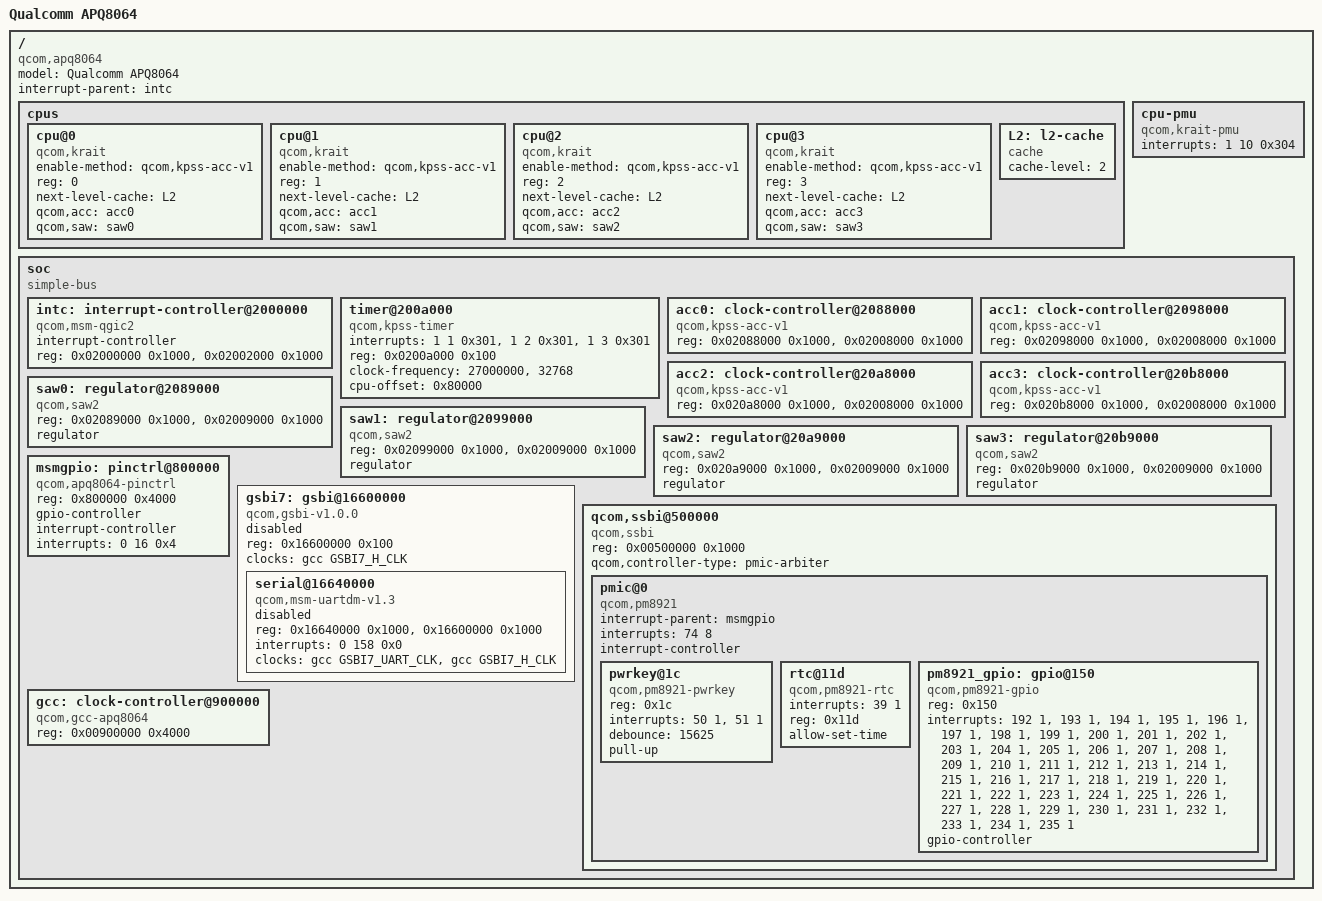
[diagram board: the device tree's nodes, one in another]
/dts-v1/;

#include "skeleton.dtsi"
#include <dt-bindings/clock/qcom,gcc-msm8960.h>
#include <dt-bindings/soc/qcom,gsbi.h>

/ {
	model = "Qualcomm APQ8064";
	compatible = "qcom,apq8064";
	interrupt-parent = <&intc>;

	cpus {
		#address-cells = <1>;
		#size-cells = <0>;

		cpu@0 {
			compatible = "qcom,krait";
			enable-method = "qcom,kpss-acc-v1";
			device_type = "cpu";
			reg = <0>;
			next-level-cache = <&L2>;
			qcom,acc = <&acc0>;
			qcom,saw = <&saw0>;
		};

		cpu@1 {
			compatible = "qcom,krait";
			enable-method = "qcom,kpss-acc-v1";
			device_type = "cpu";
			reg = <1>;
			next-level-cache = <&L2>;
			qcom,acc = <&acc1>;
			qcom,saw = <&saw1>;
		};

		cpu@2 {
			compatible = "qcom,krait";
			enable-method = "qcom,kpss-acc-v1";
			device_type = "cpu";
			reg = <2>;
			next-level-cache = <&L2>;
			qcom,acc = <&acc2>;
			qcom,saw = <&saw2>;
		};

		cpu@3 {
			compatible = "qcom,krait";
			enable-method = "qcom,kpss-acc-v1";
			device_type = "cpu";
			reg = <3>;
			next-level-cache = <&L2>;
			qcom,acc = <&acc3>;
			qcom,saw = <&saw3>;
		};

		L2: l2-cache {
			compatible = "cache";
			cache-level = <2>;
		};
	};

	cpu-pmu {
		compatible = "qcom,krait-pmu";
		interrupts = <1 10 0x304>;
	};

	soc: soc {
		#address-cells = <1>;
		#size-cells = <1>;
		ranges;
		compatible = "simple-bus";

		intc: interrupt-controller@2000000 {
			compatible = "qcom,msm-qgic2";
			interrupt-controller;
			#interrupt-cells = <3>;
			reg = <0x02000000 0x1000>,
			      <0x02002000 0x1000>;
		};

		timer@200a000 {
			compatible = "qcom,kpss-timer", "qcom,msm-timer";
			interrupts = <1 1 0x301>,
				     <1 2 0x301>,
				     <1 3 0x301>;
			reg = <0x0200a000 0x100>;
			clock-frequency = <27000000>,
					  <32768>;
			cpu-offset = <0x80000>;
		};

		acc0: clock-controller@2088000 {
			compatible = "qcom,kpss-acc-v1";
			reg = <0x02088000 0x1000>, <0x02008000 0x1000>;
		};

		acc1: clock-controller@2098000 {
			compatible = "qcom,kpss-acc-v1";
			reg = <0x02098000 0x1000>, <0x02008000 0x1000>;
		};

		acc2: clock-controller@20a8000 {
			compatible = "qcom,kpss-acc-v1";
			reg = <0x020a8000 0x1000>, <0x02008000 0x1000>;
		};

		acc3: clock-controller@20b8000 {
			compatible = "qcom,kpss-acc-v1";
			reg = <0x020b8000 0x1000>, <0x02008000 0x1000>;
		};

		saw0: regulator@2089000 {
			compatible = "qcom,saw2";
			reg = <0x02089000 0x1000>, <0x02009000 0x1000>;
			regulator;
		};

		saw1: regulator@2099000 {
			compatible = "qcom,saw2";
			reg = <0x02099000 0x1000>, <0x02009000 0x1000>;
			regulator;
		};

		saw2: regulator@20a9000 {
			compatible = "qcom,saw2";
			reg = <0x020a9000 0x1000>, <0x02009000 0x1000>;
			regulator;
		};

		saw3: regulator@20b9000 {
			compatible = "qcom,saw2";
			reg = <0x020b9000 0x1000>, <0x02009000 0x1000>;
			regulator;
		};

		msmgpio: pinctrl@800000 {
			compatible = "qcom,apq8064-pinctrl";
			reg = <0x800000 0x4000>;

			gpio-controller;
			#gpio-cells = <2>;
			interrupt-controller;
			#interrupt-cells = <2>;
			interrupts = <0 16 0x4>;
		};

		gsbi7: gsbi@16600000 {
			status = "disabled";
			compatible = "qcom,gsbi-v1.0.0";
			reg = <0x16600000 0x100>;
			clocks = <&gcc GSBI7_H_CLK>;
			clock-names = "iface";
			#address-cells = <1>;
			#size-cells = <1>;
			ranges;

			serial@16640000 {
				compatible = "qcom,msm-uartdm-v1.3", "qcom,msm-uartdm";
				reg = <0x16640000 0x1000>,
				      <0x16600000 0x1000>;
				interrupts = <0 158 0x0>;
				clocks = <&gcc GSBI7_UART_CLK>, <&gcc GSBI7_H_CLK>;
				clock-names = "core", "iface";
				status = "disabled";
			};
		};

		qcom,ssbi@500000 {
			compatible = "qcom,ssbi";
			reg = <0x00500000 0x1000>;
			qcom,controller-type = "pmic-arbiter";

			pmic@0 {
				compatible = "qcom,pm8921";
				interrupt-parent = <&msmgpio>;
				interrupts = <74 8>;
				#interrupt-cells = <2>;
				interrupt-controller;
				#address-cells = <1>;
				#size-cells = <0>;

				pwrkey@1c {
					compatible = "qcom,pm8921-pwrkey";
					reg = <0x1c>;
					interrupts = <50 1>, <51 1>;
					debounce = <15625>;
					pull-up;
				};

				rtc@11d {
					compatible = "qcom,pm8921-rtc";
					interrupts = <39 1>;
					reg = <0x11d>;
					allow-set-time;
				};

				pm8921_gpio: gpio@150 {
					compatible = "qcom,pm8921-gpio";
					reg = <0x150>;
					interrupts = <192 1>, <193 1>, <194 1>,
						     <195 1>, <196 1>, <197 1>,
						     <198 1>, <199 1>, <200 1>,
						     <201 1>, <202 1>, <203 1>,
						     <204 1>, <205 1>, <206 1>,
						     <207 1>, <208 1>, <209 1>,
						     <210 1>, <211 1>, <212 1>,
						     <213 1>, <214 1>, <215 1>,
						     <216 1>, <217 1>, <218 1>,
						     <219 1>, <220 1>, <221 1>,
						     <222 1>, <223 1>, <224 1>,
						     <225 1>, <226 1>, <227 1>,
						     <228 1>, <229 1>, <230 1>,
						     <231 1>, <232 1>, <233 1>,
						     <234 1>, <235 1>;

					gpio-controller;
					#gpio-cells = <2>;
				};
			};
		};

		gcc: clock-controller@900000 {
			compatible = "qcom,gcc-apq8064";
			reg = <0x00900000 0x4000>;
			#clock-cells = <1>;
			#reset-cells = <1>;
		};
	};
};
